AUTOSAR XML (schema 4-2-2)
package /ComponentTypes
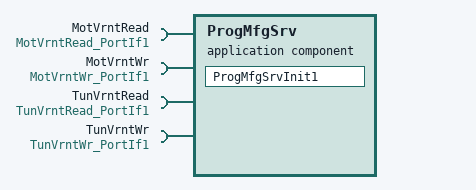
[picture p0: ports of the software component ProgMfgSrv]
  application sw component type ProgMfgSrv
    4 x require port, all with client-com-spec=Oper:
      MotVrntRead: required-interface=MotVrntRead_PortIf1
      MotVrntWr: required-interface=MotVrntWr_PortIf1
      TunVrntRead: required-interface=TunVrntRead_PortIf1
      TunVrntWr: required-interface=TunVrntWr_PortIf1
    behavior ProgMfgSrv_InternalBehavior
      init event PartNrPer1_InitEvent: start-on-event=ProgMfgSrvInit1
      runnable ProgMfgSrvInit1
        4 x sync call, all with timeout=0:
          SC_MotVrntRead_Oper: operation=MotVrntRead.Oper
          SC_MotVrntWr_Oper: operation=MotVrntWr.Oper
          SC_TunVrntRead_Oper: operation=TunVrntRead.Oper
          SC_TunVrntWr_Oper: operation=TunVrntWr.Oper
  swc implementation ProgMfgSrv_Implementation: behavior=ProgMfgSrv_InternalBehavior
    code-descriptors:
      code Default: artifact-descriptors=autosar-engineering-object={short-label=Default, category=SWSRC}
